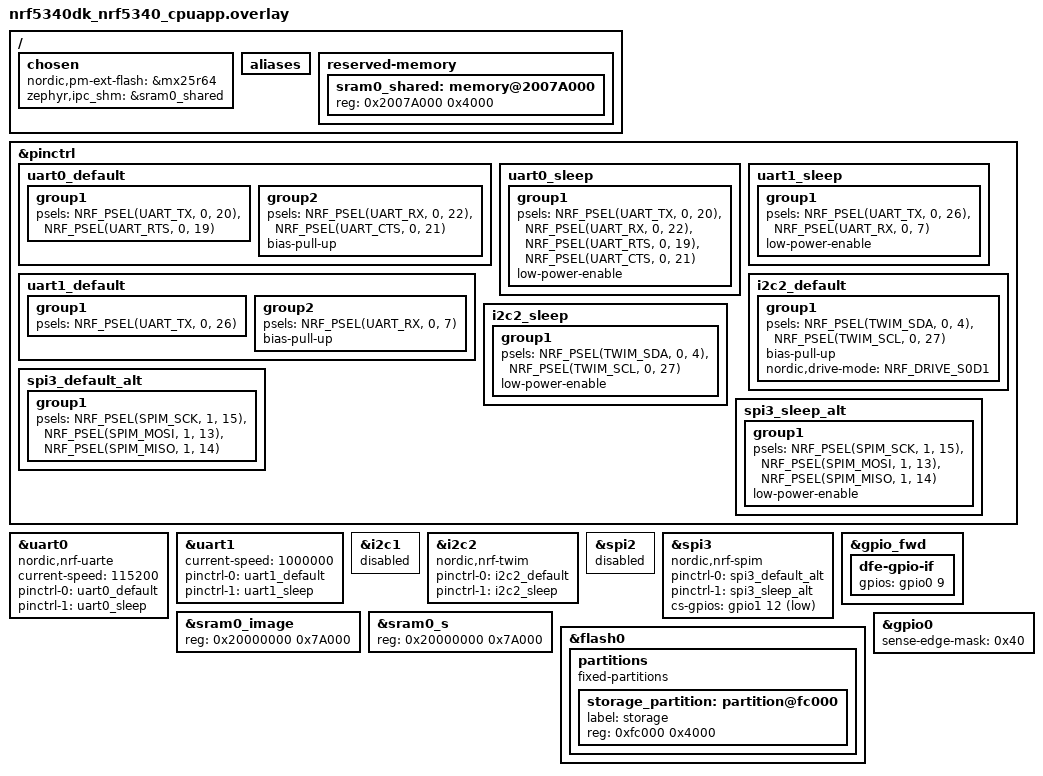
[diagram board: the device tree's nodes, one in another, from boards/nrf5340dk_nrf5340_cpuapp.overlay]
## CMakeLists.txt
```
# SPDX-License-Identifier: Apache-2.0

cmake_minimum_required(VERSION 3.13.1)

# set(mcuboot_DTC_OVERLAY_FILE ${CMAKE_CURRENT_SOURCE_DIR}/child_image/mcuboot.overlay)
find_package(Zephyr REQUIRED HINTS $ENV{ZEPHYR_BASE})
project(comprensive_example)

# NORDIC SDK APP START

target_sources(app PRIVATE src/main.c)

target_sources_ifdef(CONFIG_EXAMPLE_I2C app
                     PRIVATE src/iic_thread.c)
					 
target_sources_ifdef(CONFIG_EXAMPLE_SPIM app
                     PRIVATE src/spi_thread.c)
					 
target_sources_ifdef(CONFIG_EXAMPLE_HS_UART app
                     PRIVATE src/uart_thread.c)
					 
target_sources_ifdef(CONFIG_EXAMPLE_ADC app
                     PRIVATE src/adc_thread.c)
					 
target_sources_ifdef(CONFIG_RPC_REMOTE_API app
                     PRIVATE src/rpc_app_api_general.c src/rpc_app_api.c src/rpc_thread.c)				 

target_sources_ifdef(CONFIG_RPC_SMP_BT app
                     PRIVATE src/rpc_app_smp_bt.c)
					 
target_sources_ifdef(CONFIG_EXAMPLE_FLASH app
                     PRIVATE src/flash_thread.c)

zephyr_library_include_directories(.)

# NORDIC SDK APP END
```

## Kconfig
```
#
# Copyright (c) 2018 Nordic Semiconductor ASA
#
# SPDX-License-Identifier: LicenseRef-BSD-5-Clause-Nordic
#

source "Kconfig.zephyr"
menu "comprehensive_rpc example"

config BLE_NETWORK_CORE
	bool "Both BLE host and controller run on network core"
	help
	  Enable the whole BLE stack running on network core

config EXAMPLE_I2C
	bool "load I2C example or not"
	help
		if yes, load I2C example
		
config EXAMPLE_SPIM
	bool "load SPI master example or not"
	help
		if yes, load SPI master example		
		
config EXAMPLE_EXT_INT
	bool "load external IO interrupt example or not"
	help
		if yes, load external IO interrupt example

config EXAMPLE_ADC
	bool "load ADC example or not"
	help
		if yes, load ADC example		

config EXAMPLE_HS_UART
	bool "load high speed UART example or not"
	help
		if yes, load high speed UART example	  

config EXAMPLE_FLASH
	bool "load Flash access usage example"
	default n
	help
		if yes, load Flash access usage example

config RPC_REMOTE_API
	bool "app core and net core communicate by remote API. that is, app core can call net core API, and net core can also call app core API"
	help
	  enable the RPC api mode
	  
config RPC_SMP_BT
	bool "load DFU example over BLE SMP"
	help
		if yes, load DFU example over BLE SMP

config RPC_REASSEMBLY_BT
	bool "enable reassembly of BT packets"
	select MCUMGR_SMP_REASSEMBLY
	help
		if yes, enable reassembly of BT packets
		
module = COMPREHENSIVE_RPC_EXAMPLE_CONFIG
module-str = comprehensive_rpc example configurations
source "${ZEPHYR_BASE}/subsys/logging/Kconfig.template.log_config"

endmenu
```

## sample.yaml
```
sample:
  name: BLE Comprehensive rpc example
  description: secondary slot on external QSPI flash. Both BT host and controller run on network core.
tests:
  samples.bluetooth.peripheral_uart:
    build_only: true
    build_on_all: true
    platform_allow: nrf5340dk_nrf5340_cpuapp
    tags: bluetooth ci_build
```

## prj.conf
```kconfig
CONFIG_NFCT_PINS_AS_GPIOS=y

## thread monitor ##
CONFIG_THREAD_ANALYZER=y
CONFIG_THREAD_NAME=y

## logging configurations ##
CONFIG_ASSERT=y
CONFIG_LOG=y
CONFIG_LOG_PRINTK=y
CONFIG_LOG_BUFFER_SIZE=8192

## Change logging backend to RTT ##
# CONFIG_LOG_BACKEND_UART=n
# CONFIG_LOG_BACKEND_RTT=y
# CONFIG_USE_SEGGER_RTT=y
# CONFIG_RTT_CONSOLE=y
# CONFIG_UART_CONSOLE=n

## peripherals ##
CONFIG_GPIO=y
CONFIG_DK_LIBRARY=y

## stack size configurations ##
CONFIG_SYSTEM_WORKQUEUE_STACK_SIZE=4096
# CONFIG_ISR_STACK_SIZE=2048
CONFIG_HEAP_MEM_POOL_SIZE=12288
CONFIG_MAIN_STACK_SIZE=2048

## I2C master example ##
CONFIG_EXAMPLE_I2C=y
CONFIG_I2C=y
CONFIG_NRFX_TWIM2=y

## external interrupt example (in IIC thread) ##
CONFIG_EXAMPLE_EXT_INT=y

## high speed uart example ##
CONFIG_EXAMPLE_HS_UART=y
CONFIG_SERIAL=y
CONFIG_UART_ASYNC_API=y
CONFIG_UART_1_ASYNC=y
CONFIG_NRFX_UARTE1=y
CONFIG_UART_1_NRF_HW_ASYNC=y
CONFIG_UART_1_NRF_HW_ASYNC_TIMER=1

## SPI master example ##
CONFIG_EXAMPLE_SPIM=y
CONFIG_SPI=y
CONFIG_NRFX_SPIM3=y

## Load ADC example ##
CONFIG_EXAMPLE_ADC=y
CONFIG_ADC=y
CONFIG_ADC_ASYNC=y
CONFIG_ADC_NRFX_SAADC=y

## Flash access usage example ##
CONFIG_EXAMPLE_FLASH=y
CONFIG_FLASH=y
CONFIG_FLASH_PAGE_LAYOUT=y
CONFIG_FLASH_MAP=y
CONFIG_NVS=y
CONFIG_MPU_ALLOW_FLASH_WRITE=y
CONFIG_SETTINGS=y

## Device power management example ##
CONFIG_PM_DEVICE=y

## RPC example configurations ##
CONFIG_RPC_REMOTE_API=y
CONFIG_NRF_RPC=y
CONFIG_NRF_RPC_CBOR=y
CONFIG_NRF_RPC_THREAD_STACK_SIZE=4096

## Common DFU settings ##
CONFIG_BLE_NETWORK_CORE=y
CONFIG_NRF53_UPGRADE_NETWORK_CORE=y
CONFIG_BOOTLOADER_MCUBOOT=y
CONFIG_BOARD_ENABLE_CPUNET=y

## Open the following configs to run nrf_dfu ##
# CONFIG_NRF_DFU=y
# CONFIG_NRF_DFU_RPC_APP=y
# CONFIG_NRF_DFU_LOG_LEVEL=3
# CONFIG_IMG_MANAGER=y
# CONFIG_MCUBOOT_IMG_MANAGER=y
# CONFIG_IMG_BLOCK_BUF_SIZE=4096

## secondary slot on external Flash ##
CONFIG_PM_PARTITION_SIZE_SETTINGS_STORAGE=0x4000
CONFIG_NORDIC_QSPI_NOR=y
CONFIG_NORDIC_QSPI_NOR_FLASH_LAYOUT_PAGE_SIZE=4096
CONFIG_NORDIC_QSPI_NOR_STACK_WRITE_BUFFER_SIZE=16
CONFIG_STREAM_FLASH=y
CONFIG_STREAM_FLASH_ERASE=y

## Open the following configs to run SMP DFU ##
CONFIG_BOOTLOADER_MCUBOOT=y
CONFIG_MCUMGR=y
CONFIG_MCUMGR_CMD_IMG_MGMT=y
CONFIG_MCUMGR_CMD_OS_MGMT=y
CONFIG_OS_MGMT_TASKSTAT=n
CONFIG_OS_MGMT_ECHO=y
CONFIG_IMG_BLOCK_BUF_SIZE=2048
CONFIG_MCUMGR_BUF_COUNT=8
CONFIG_OS_MGMT_MCUMGR_PARAMS=y
# Enable the storage erase command.
CONFIG_MCUMGR_GRP_ZEPHYR_BASIC=y
CONFIG_MCUMGR_GRP_BASIC_CMD_STORAGE_ERASE=y

CONFIG_RPC_SMP_BT=y

## open the following configurations if you want to get a faster DFU speed
CONFIG_RPC_REASSEMBLY_BT=y
CONFIG_MCUMGR_BUF_SIZE=2475
CONFIG_MCUMGR_BUF_COUNT=4

# FLASH nop device is enabled to prevent bus faults when mcumgr tries to access
# simulated partition with network core image data.
# CONFIG_FLASH_NOP_DEVICE=y

# update application core and network core together in a zip file
CONFIG_MCUBOOT_IMAGE_VERSION="1.0.0+0"
CONFIG_UPDATEABLE_IMAGE_NUMBER=2
CONFIG_IMG_ERASE_PROGRESSIVELY=y
CONFIG_NRF53_UPGRADE_NETWORK_CORE=y
```

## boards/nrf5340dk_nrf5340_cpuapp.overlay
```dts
/* overlay file for app core */

/ {
	chosen {
		nordic,pm-ext-flash = &mx25r64;
	};
};

&pinctrl {
	uart0_default: uart0_default {
		group1 {
			psels = <NRF_PSEL(UART_TX, 0, 20)>,
				<NRF_PSEL(UART_RTS, 0, 19)>;
		};
		group2 {
			psels = <NRF_PSEL(UART_RX, 0, 22)>,
				<NRF_PSEL(UART_CTS, 0, 21)>;
			bias-pull-up;
		};
	};

	uart0_sleep: uart0_sleep {
		group1 {
			psels = <NRF_PSEL(UART_TX, 0, 20)>,
				<NRF_PSEL(UART_RX, 0, 22)>,
				<NRF_PSEL(UART_RTS, 0, 19)>,
				<NRF_PSEL(UART_CTS, 0, 21)>;
			low-power-enable;
		};
	};

	uart1_default: uart1_default {
		group1 {
			psels = <NRF_PSEL(UART_TX, 0, 26)>;
		};
		group2 {
			psels = <NRF_PSEL(UART_RX, 0, 7)>;
			bias-pull-up;
		};
	};

	uart1_sleep: uart1_sleep {
		group1 {
			psels = <NRF_PSEL(UART_TX, 0, 26)>,
				<NRF_PSEL(UART_RX, 0, 7)>;
			low-power-enable;
		};
	};

	i2c2_default: i2c2_default {
		group1 {
			psels = <NRF_PSEL(TWIM_SDA, 0, 4)>,
				<NRF_PSEL(TWIM_SCL, 0, 27)>;
			bias-pull-up;
			nordic,drive-mode = <NRF_DRIVE_S0D1>;				
		};
	};

	i2c2_sleep: i2c2_sleep {
		group1 {
			psels = <NRF_PSEL(TWIM_SDA, 0, 4)>,
				<NRF_PSEL(TWIM_SCL, 0, 27)>;
			low-power-enable;
		};
	};	

	spi3_default_alt: spi3_default_alt {
		group1 {
			psels = <NRF_PSEL(SPIM_SCK, 1, 15)>,
				<NRF_PSEL(SPIM_MOSI, 1, 13)>,
				<NRF_PSEL(SPIM_MISO, 1, 14)>;
		};
	};

	spi3_sleep_alt: spi3_sleep_alt {
		group1 {
			psels = <NRF_PSEL(SPIM_SCK, 1, 15)>,
				<NRF_PSEL(SPIM_MOSI, 1, 13)>,
				<NRF_PSEL(SPIM_MISO, 1, 14)>;
			low-power-enable;
		};
	};
};


&uart0 {
	compatible = "nordic,nrf-uarte";
	status = "okay";
	current-speed = < 115200 >;
	pinctrl-0 = < &uart0_default >;
	pinctrl-1 = < &uart0_sleep >;
	pinctrl-names = "default", "sleep";	
	/* delete rts-pin&cts-pin to release the related 2 pins for other uses */
	/delete-property/ rts-pin;
	/delete-property/ cts-pin;
};

&uart1 {
	status = "okay";
	current-speed = < 1000000 >;
	pinctrl-0 = < &uart1_default >;
	pinctrl-1 = < &uart1_sleep >;
	pinctrl-names = "default", "sleep";	
};

&i2c1 {
	status = "disabled";
};

my_i2c: &i2c2 {
	status = "okay";
	compatible = "nordic,nrf-twim";
	pinctrl-0 = < &i2c2_default >;
	pinctrl-1 = < &i2c2_sleep >;
	pinctrl-names = "default", "sleep";	
};

&spi2 {
	status = "disabled";
};

my_spi: &spi3 {
	status = "okay"; 
	compatible = "nordic,nrf-spim";
	pinctrl-0 = <&spi3_default_alt>;
	pinctrl-1 = <&spi3_sleep_alt>;
	pinctrl-names = "default", "sleep";	
	cs-gpios = <&gpio1 12 GPIO_ACTIVE_LOW>;
};

/* delete button4 to initialize the related pin for network core use */
/ {
 aliases {  
  /delete-property/ sw3;
 };
};

/delete-node/ &button3;

&gpio_fwd {
	dfe-gpio-if {
		gpios = <&gpio0 9 0>;
		};
};

/* adjust the RAM size of application image */
&sram0_image{
	reg = < 0x20000000 0x7A000 >;
};

&sram0_s{
	reg = < 0x20000000 0x7A000 >;
};

/delete-node/ &sram0_shared;

/ {
	chosen {
		/* shared memory reserved for the inter-processor communication */
		zephyr,ipc_shm = &sram0_shared;
	};

	reserved-memory {
		#address-cells = <1>;
		#size-cells = <1>;
		ranges;	
		sram0_shared: memory@2007A000 {
			/* SRAM allocated to shared memory */
			reg = <0x2007A000 0x4000>;
		};
	};
};

/delete-node/ &storage_partition;
&flash0{
		partitions {
			compatible = "fixed-partitions";
			#address-cells = < 0x1 >;
			#size-cells = < 0x1 >;

			storage_partition: partition@fc000 {
				label = "storage";
				reg = < 0xfc000 0x4000 >;
			};
		};
};

&gpio0 {
	/* pin6 sense for edge */
	sense-edge-mask = <0x40>;
};
```

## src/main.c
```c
/*
 * Copyright (c) 2020 Nordic Semiconductor ASA
 *
 * SPDX-License-Identifier: LicenseRef-BSD-5-Clause-Nordic
 */

#include <zephyr/kernel.h>
#include <zephyr/device.h>
#include <zephyr/devicetree.h>
#include <zephyr/drivers/gpio.h>
#include <stdio.h>
#include <dk_buttons_and_leds.h>
#include <nrf.h>
#include <nrfx.h>
#include <zephyr/drivers/uart.h>
#ifdef CONFIG_MCUMGR_CMD_IMG_MGMT
#include "img_mgmt/img_mgmt.h"
#endif
#ifdef CONFIG_MCUMGR_CMD_OS_MGMT
#include "os_mgmt/os_mgmt.h"
#endif
#ifdef CONFIG_RPC_SMP_BT
#include "rpc_app_smp_bt.h"
#include <img_mgmt/img_mgmt_impl.h>
#endif
#ifdef CONFIG_NRF_DFU
#include "nrf_dfu_settings.h"
#include "nrf_dfu.h"
#include <zephyr/sys/reboot.h>
#include "nrf_dfu.h"
#include "nrf_dfu_validation.h"
#endif
#include <zephyr/logging/log.h>
#include <zephyr/logging/log_ctrl.h>
#include <zephyr/pm/device.h>

#define LOG_MODULE_NAME main
LOG_MODULE_REGISTER(LOG_MODULE_NAME);

#define ERASE_DELAY_AFTER_BOOT 30   //unit: s
static struct k_work_delayable blinky_work;

K_SEM_DEFINE(sem_rpc_tx, 0, 1);
K_SEM_DEFINE(sem_spi_txrx, 0, 1);

/* Stack definition for application workqueue */
K_THREAD_STACK_DEFINE(application_stack_area,
		      1024);
static struct k_work_q application_work_q;

/* The devicetree node identifier for the "led0" alias. */
#define LED0_NODE DT_ALIAS(led0)

#if DT_NODE_HAS_STATUS(LED0_NODE, okay)
#define LED0	DT_GPIO_CTLR(LED0_NODE, gpios)
#define LED0_PIN	DT_GPIO_PIN(LED0_NODE, gpios)
#define LED0_FLAGS	DT_GPIO_FLAGS(LED0_NODE, gpios)
#else
/* A build error here means your board isn't set up to blink an LED. */
#error "Unsupported board: led0 devicetree alias is not defined"
#define LED0	""
#define PIN	0
#define FLAGS	0
#endif

#ifdef CONFIG_PM_DEVICE
const struct device *devUart0;
const struct device *devUart1;
static void get_device_handles(void)
{
	devUart0 = device_get_binding("UART_0");
    devUart1 = device_get_binding("UART_1");
}

void set_device_pm_state(void)
{
	int err;
	enum pm_device_state pm_state;

	if (devUart1)
	{
		pm_device_state_get(devUart1, &pm_state);
		if (pm_state == PM_DEVICE_STATE_SUSPENDED)
		{
			LOG_INF("UART1 is in low power state. We activate it");
			err = pm_device_action_run(devUart1,PM_DEVICE_ACTION_RESUME);
			if (err) {
				LOG_ERR("UART1 enable failed");			
			}
			else
			{
				LOG_INF("## UART1 is active now ##");
			}		
		}
		else if (pm_state == PM_DEVICE_STATE_ACTIVE)
		{
			LOG_INF("UART1 is in active state. We suspend it");

#if CONFIG_UART_ASYNC_API && CONFIG_UART_1_NRF_HW_ASYNC
		((const struct uart_driver_api *)devUart1->api)->rx_disable(devUart1);
#endif			
			err = pm_device_action_run(devUart1,	PM_DEVICE_ACTION_SUSPEND);
			if (err) {
				LOG_ERR("UART1 disable failed");
			}
			else
			{
				LOG_INF("## UART1 is suspended now ##");
			}		
		}
	}

	pm_device_state_get(devUart0, &pm_state);
	if (pm_state == PM_DEVICE_STATE_SUSPENDED)
	{
		LOG_INF("UART0 is in low power state. We activate it");
		err = pm_device_action_run(devUart0,	PM_DEVICE_ACTION_RESUME);
		if (err) {
			LOG_ERR("UART0 enable failed");			
		}
		else
		{
			LOG_INF("## UART0 is active now ##");
		}		
	}
	else if (pm_state == PM_DEVICE_STATE_ACTIVE)
	{
		LOG_INF("UART0 is in active state. We suspend it");
		//print out all the pending logging messages
		while(log_process());

#if CONFIG_UART_ASYNC_API && CONFIG_UART_0_NRF_HW_ASYNC
		((const struct uart_driver_api *)devUart0->api)->rx_disable(devUart0);
#endif
		err = pm_device_action_run(devUart0,	PM_DEVICE_ACTION_SUSPEND);
		if (err) {
			LOG_ERR("UART0 disable failed");
		}
		else
		{
			LOG_INF("## UART0 is suspended now ##");
		}		
	}

}

#endif //CONFIG_PM_DEVICE

void button_changed(uint32_t button_state, uint32_t has_changed)
{
	uint32_t buttons = button_state & has_changed;
	
	if (buttons & DK_BTN1_MSK) {
		LOG_INF("button1 isr");
		k_sem_give(&sem_rpc_tx);		
	}

	if (buttons & DK_BTN2_MSK) {
		LOG_INF("button2 isr");
		k_sem_give(&sem_spi_txrx);
	}

	if (buttons & DK_BTN3_MSK) {
		LOG_INF("button3 isr");
#ifdef CONFIG_PM_DEVICE		
		set_device_pm_state();
#endif		
	}			
}

const struct device *ledDev;
bool led_is_on = true;

static void blinky_work_fn(struct k_work *work)
{
    //printk("blinky fn in system workqueue\n");
	gpio_pin_set(ledDev, LED0_PIN, (int)led_is_on);
	led_is_on = !led_is_on;

	k_work_reschedule_for_queue(&application_work_q, &blinky_work,
					   	K_SECONDS(2));

}

static void assign_io_to_netcore(void)
{
	NRF_P0_S->PIN_CNF[9] = (GPIO_PIN_CNF_MCUSEL_NetworkMCU <<
					GPIO_PIN_CNF_MCUSEL_Pos);
}

#ifdef CONFIG_NRF_DFU
/**@brief Function for handling DFU events.
 */
static void dfu_observer(nrf_dfu_evt_type_t evt_type)
{
    switch (evt_type)
    {
        case NRF_DFU_EVT_DFU_STARTED:
        case NRF_DFU_EVT_OBJECT_RECEIVED:

            break;
        case NRF_DFU_EVT_DFU_COMPLETED:
        case NRF_DFU_EVT_DFU_ABORTED:
			LOG_INF("resetting...");
			while(log_process());
            sys_reboot(SYS_REBOOT_WARM);
            break;
        case NRF_DFU_EVT_TRANSPORT_DEACTIVATED:
            // Reset the internal state of the DFU settings to the last stored state.
			LOG_INF("NRF_DFU_EVT_TRANSPORT_DEACTIVATED");
            nrf_dfu_settings_reinit();
            break;
        default:
            break;
    }

}

int dfu_init(void)
{
    int ret_val;

    ret_val = nrf_dfu_settings_init(true);
    if (ret_val != NRF_SUCCESS)
	{
		LOG_WRN("dfu settings init err %d", ret_val);
	}

    ret_val = nrf_dfu_init(dfu_observer);
    if (ret_val != NRF_SUCCESS)
	{
		LOG_WRN("dfu init err %d", ret_val);
	}

    return ret_val;
}
#endif //CONFIG_NRF_DFU

void main(void)
{
	int err;	

	LOG_INF("### comprehensive example @ appcore version v0.5 compiled at %s %s\n", __TIME__, __DATE__);
	// assign_io_to_netcore();  //It's now replaced by device tree configurations

	ledDev = DEVICE_DT_GET(LED0);
	if (ledDev == NULL) {
		return;
	}

#ifdef CONFIG_PM_DEVICE
	get_device_handles();
#endif

	err = gpio_pin_configure(ledDev, LED0_PIN, GPIO_OUTPUT_ACTIVE | LED0_FLAGS);
	if (err < 0) {
		printk("gpio configure error %d \n", err);
		return;
	}

	err = dk_buttons_init(button_changed);
	if (err) {
		printk("Cannot init buttons (err: %d)", err);
	}

	k_work_queue_start(&application_work_q, application_stack_area,
			   K_THREAD_STACK_SIZEOF(application_stack_area), 10,
			   NULL);
	k_work_init_delayable(&blinky_work, blinky_work_fn);
	k_work_reschedule_for_queue(&application_work_q, &blinky_work,
					   	K_MSEC(20));	

#ifdef CONFIG_RPC_SMP_BT
	LOG_INF("## OTA/Serial DFU example ##");	
#ifdef CONFIG_MCUMGR_CMD_OS_MGMT
	os_mgmt_register_group();
#endif	
#ifdef CONFIG_MCUMGR_CMD_IMG_MGMT
	img_mgmt_register_group();
#endif //CONFIG_MCUMGR_CMD_IMG_MGMT
#endif  //CONFIG_RPC_SMP_BT

#ifdef CONFIG_NRF_DFU
	err = dfu_init();
	if (err) {
		LOG_ERR("dfu service init err %d", err);		
	}
#endif //CONFIG_NRF_DFU
	//main thread 
	while(1)
	{
		//add your code here
		k_sleep(K_SECONDS(5));
		LOG_INF("main thread");
	}
}
```

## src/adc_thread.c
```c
/*
 * Copyright (c) 2020 Nordic Semiconductor ASA
 *
 * SPDX-License-Identifier: LicenseRef-BSD-5-Clause-Nordic
 */

#include <zephyr/zephyr.h>
#include <zephyr/device.h>
#include <zephyr/devicetree.h>
#include <zephyr/drivers/gpio.h>
#include <zephyr/logging/log.h>
#include <zephyr/drivers/adc.h>
#include <hal/nrf_saadc.h>

LOG_MODULE_REGISTER(adc_thread, 3);

#define NUM_OF_CH 2
#define ADC_DEVICE_NAME		DT_LABEL(DT_NODELABEL(adc))
#define ADC_RESOLUTION		12
#define ADC_OVERSAMPLING	4 /* 2^ADC_OVERSAMPLING samples are averaged */
#define ADC_MAX 		4096
#define BATTERY_MEAS_VOLTAGE_GAIN	6
#define ADC_GAIN		ADC_GAIN_1_6
#define ADC_REFERENCE		ADC_REF_INTERNAL
#define ADC_REF_INTERNAL_MV	600UL
#define ADC_ACQUISITION_TIME	ADC_ACQ_TIME(ADC_ACQ_TIME_MICROSECONDS, 10)
#define ADC_CHANNEL_ID		0
#define ADC_CHANNEL_INPUT	NRF_SAADC_INPUT_VDD
#define ADC_CHANNEL_ID2		1
#define ADC_CHANNEL_INPUT2	NRF_SAADC_INPUT_AIN1   //P0.05
/* ADC asynchronous read is scheduled on odd works. Value read happens during
 * even works. This is done to avoid creating a thread for battery monitor.
 */
#define ADC_SAMPLE_INTERVAL	20  //unit:s

#define BATTERY_VOLTAGE(sample) (sample * BATTERY_MEAS_VOLTAGE_GAIN	\
				 * ADC_REF_INTERNAL_MV / ADC_MAX)


static const struct device *adc_dev;
static int16_t adc_buffer[NUM_OF_CH];
static bool adc_async_read_pending;
static struct k_work_delayable adc_work;

static struct k_poll_signal async_sig = K_POLL_SIGNAL_INITIALIZER(async_sig);
static struct k_poll_event  async_evt =
	K_POLL_EVENT_INITIALIZER(K_POLL_TYPE_SIGNAL,
				 K_POLL_MODE_NOTIFY_ONLY,
				 &async_sig);

static struct adc_sequence sequence = {
	.options	= NULL,
	.channels	= BIT(ADC_CHANNEL_ID),
	.buffer		= adc_buffer,
	.buffer_size	= sizeof(adc_buffer),
	.resolution	= ADC_RESOLUTION,
	.oversampling	= ADC_OVERSAMPLING,
	.calibrate	= false,
};
static struct adc_sequence sequence_calibrate = {
	.options	= NULL,
	.channels	= BIT(ADC_CHANNEL_ID),
	.buffer		= adc_buffer,
	.buffer_size	= sizeof(adc_buffer),
	.resolution	= ADC_RESOLUTION,
	.oversampling	= ADC_OVERSAMPLING,
	.calibrate	= true,
};

static bool calibrated;

void adc_sample_sync(void)
{
	int err;

	if (NUM_OF_CH == 2)
	{
		sequence.channels = BIT(ADC_CHANNEL_ID) | BIT(ADC_CHANNEL_ID2);
		sequence_calibrate.channels = BIT(ADC_CHANNEL_ID) | BIT(ADC_CHANNEL_ID2);
		sequence.oversampling  = NRF_SAADC_OVERSAMPLE_DISABLED;
		sequence_calibrate.oversampling  = NRF_SAADC_OVERSAMPLE_DISABLED;
	}
	if (likely(calibrated)) {		
		err = adc_read(adc_dev, &sequence);
	} else {
		err = adc_read(adc_dev, &sequence_calibrate);
		calibrated = true;
	}
	if (err) {
		LOG_WRN("ADC read err %d", err);
	} else {
		for (int i = 0; i < NUM_OF_CH; i++)
		{
			uint32_t voltage = BATTERY_VOLTAGE(adc_buffer[i]);
			LOG_INF("Voltage%d: %u mV / %d", i, voltage, adc_buffer[i]);
		}
	}			
}
#ifdef CONFIG_ADC_ASYNC
static void adc_sample_async(struct k_work *work)
{
	int err;

	if (NUM_OF_CH == 2)
	{
		sequence.channels = BIT(ADC_CHANNEL_ID) | BIT(ADC_CHANNEL_ID2);
		sequence_calibrate.channels = BIT(ADC_CHANNEL_ID) | BIT(ADC_CHANNEL_ID2);
		sequence.oversampling  = NRF_SAADC_OVERSAMPLE_DISABLED;
		sequence_calibrate.oversampling  = NRF_SAADC_OVERSAMPLE_DISABLED;		
	}
	if (!adc_async_read_pending) {
		if (likely(calibrated)) {
			err = adc_read_async(adc_dev, &sequence, &async_sig);
		} else {
			err = adc_read_async(adc_dev, &sequence_calibrate,
					     &async_sig);
			calibrated = true;
		}

		if (err) {
			LOG_WRN("adc_read_async err %d", err);
		} else {
			adc_async_read_pending = true;
		}
	} else {
		err = k_poll(&async_evt, 1, K_NO_WAIT);
		if (err) {
			LOG_WRN("ADC sampling timeout");
		} else {
			adc_async_read_pending = false;			
			for (int i = 0; i < NUM_OF_CH; i++)
			{
				uint32_t voltage = BATTERY_VOLTAGE(adc_buffer[i]);
				LOG_INF("Voltage%d: %u mV / %d async", i, voltage, adc_buffer[i]);
			}			
		}
	}

	k_work_reschedule(&adc_work, K_SECONDS(ADC_SAMPLE_INTERVAL));

}
#endif

static int init_adc(void)
{
	int err;

	adc_dev = device_get_binding(ADC_DEVICE_NAME);
	if (!adc_dev) {
		LOG_ERR("Cannot get ADC device");
		return -ENXIO;
	}

	struct adc_channel_cfg channel_cfg = {
		.gain             = ADC_GAIN,
		.reference        = ADC_REFERENCE,
		.acquisition_time = ADC_ACQUISITION_TIME,
		.channel_id       = ADC_CHANNEL_ID,
		.differential	  = 0,
#if defined(CONFIG_ADC_CONFIGURABLE_INPUTS)
		.input_positive   = ADC_CHANNEL_INPUT,
#endif
	};
	err = adc_channel_setup(adc_dev, &channel_cfg);
	if (err) {
		LOG_ERR("Setting up the ADC channel%d failed", ADC_CHANNEL_ID);
		return err;
	}

	if (NUM_OF_CH == 2)
	{
		channel_cfg.channel_id = ADC_CHANNEL_ID2;
		channel_cfg.input_positive = ADC_CHANNEL_INPUT2;
		err = adc_channel_setup(adc_dev, &channel_cfg);
		if (err) {
			LOG_ERR("Setting up the ADC channel%d failed", ADC_CHANNEL_ID2);
			return err;
		}		
	}


#ifdef CONFIG_ADC_ASYNC
	k_work_init_delayable(&adc_work, adc_sample_async);
	k_work_reschedule(&adc_work, K_MSEC(10));
#endif //CONFIG_ADC_ASYNC

	return 0;
}


void adc_thread(void)
{	
	
	LOG_INF("**ADC sampling example");
	init_adc();

	while (1) {                
        LOG_INF("ADC thread");
        adc_sample_sync();
        k_sleep(K_SECONDS(ADC_SAMPLE_INTERVAL)); 
	}
}

K_THREAD_DEFINE(adc_thread_id, 1024, adc_thread, NULL, NULL,
		NULL, 8, 0, 0);
```

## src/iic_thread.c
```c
/*
 * Copyright (c) 2020 Nordic Semiconductor ASA
 *
 * SPDX-License-Identifier: LicenseRef-BSD-5-Clause-Nordic
 */

#include <zephyr/kernel.h>
#include <zephyr/device.h>
#include <zephyr/devicetree.h>
#include <zephyr/drivers/gpio.h>
#include <zephyr/drivers/i2c.h>
#include <zephyr/logging/log.h>

#define LOG_MODULE_NAME i2c_thread
LOG_MODULE_REGISTER(LOG_MODULE_NAME);

const struct device *i2c_dev;
const static struct device *gpio_dev;
//static struct k_delayed_work read_eeprom;
K_SEM_DEFINE(sem_iic_op, 0, 1);

#define EXT_INT_IO	6  //p0.06
#define EXT_INT_CONF	(GPIO_INPUT | GPIO_PULL_UP)

static struct gpio_callback ext_int_cb_data;

#define EEPROM_SIM_SIZE                   (320u) //!< Simulated EEPROM size.

#define EEPROM_SIM_ADDR                   0x50    //!< Simulated EEPROM TWI slave address.

/* Slave memory addressing byte length */
#define EEPROM_SIM_ADDRESS_LEN_BYTES    2

#define IN_LINE_PRINT_CNT   (16u)   //!< Number of data bytes printed in a single line.


static int eeprom_read(uint16_t addr, uint8_t * pdata, size_t size)
{
    int ret;
    if (size > (EEPROM_SIM_SIZE))
    {
        return EINVAL;
    }
    do
    {
       uint16_t addr16 = addr;
       ret = i2c_write(i2c_dev, (uint8_t *)&addr16, EEPROM_SIM_ADDRESS_LEN_BYTES, EEPROM_SIM_ADDR);
       if (0 != ret)
       {
           break;
       }
       ret = i2c_read(i2c_dev, pdata, size, EEPROM_SIM_ADDR);
    }while (0);
    return ret;
}

static void eeprom_cmd_read(void)
{    
    uint8_t buf[IN_LINE_PRINT_CNT+1];

    for (uint16_t addr = 0; addr < EEPROM_SIM_SIZE; addr += IN_LINE_PRINT_CNT)
    {
        int err_code;
        err_code = eeprom_read(addr, buf, IN_LINE_PRINT_CNT);
        buf[IN_LINE_PRINT_CNT] = '\0';
        if (0 != err_code)
        {
            LOG_ERR("EEPROM transmission error %d\n", err_code);
            return;
        }

        LOG_HEXDUMP_INF(buf, IN_LINE_PRINT_CNT, "EEPROM: ");        
      
    }
}


void ext_int_isr(const struct device *dev, struct gpio_callback *cb,
		    uint32_t pins)
{
	LOG_INF("external interrupt occurs at %x", pins);   
    k_sem_give(&sem_iic_op);    
}

#ifdef CONFIG_EXAMPLE_EXT_INT
void config_io_interrupt(void)
{
	int ret;

	gpio_dev = device_get_binding(DT_NODE_FULL_NAME(DT_NODELABEL(gpio0)));
	if (!gpio_dev) {
		LOG_ERR("Error: didn't find GPIO_0\n");
		return;
	}

	ret = gpio_pin_configure(gpio_dev, EXT_INT_IO, EXT_INT_CONF);
	if (ret != 0) {
		LOG_ERR("Error %d: failed to configure pin %d\n",
		       ret, EXT_INT_IO);
	}

	ret = gpio_pin_interrupt_configure(gpio_dev,
					   EXT_INT_IO,
					   GPIO_INT_EDGE_FALLING);
	if (ret != 0) {
		LOG_ERR("Error %d: failed to configure interrupt on pin %d\n",
			ret, EXT_INT_IO);
	}

	gpio_init_callback(&ext_int_cb_data, ext_int_isr, BIT(EXT_INT_IO));
	gpio_add_callback(gpio_dev, &ext_int_cb_data);
	LOG_INF("**External interrupt example at P0.%d\n", EXT_INT_IO);
}
#endif //CONFIG_EXAMPLE_EXT_INT

void iic_thread(void)
{
	
	LOG_INF("** I2C master example **");
	LOG_INF("This example is ported from nRF5_SDK\\examples\\peripheral\\twi_master_with_twis_slave");
	LOG_INF("The related twis example is from nRF5_SDK\\examples\\peripheral\\twi_master_with_twis_slave");	
	
	i2c_dev = device_get_binding(DT_NODE_FULL_NAME(DT_NODELABEL(my_i2c)));
	if (!i2c_dev) {
		LOG_ERR("I2C Device driver not found");
		return;
	}
    uint32_t i2c_cfg = I2C_SPEED_SET(I2C_SPEED_FAST) | I2C_MODE_MASTER;
    if (i2c_configure(i2c_dev, i2c_cfg)) {
        LOG_ERR("I2C config failed");
        return;
    }
#ifdef CONFIG_EXAMPLE_EXT_INT
    config_io_interrupt();    
#endif
    
	// k_delayed_work_init(&read_eeprom, eeprom_read_fn);
    // k_delayed_work_submit(&read_eeprom, K_MSEC(50));	    

	while (1) {        
        k_sem_take(&sem_iic_op, K_FOREVER);
        LOG_INF("i2c master thread");
        eeprom_cmd_read();
        k_sleep(K_SECONDS(2));
	}
}

K_THREAD_DEFINE(iic_thread_id, 1024, iic_thread, NULL, NULL,
		NULL, 7, 0, 0);
```

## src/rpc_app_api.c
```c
/*
 * Copyright (c) 2020 Nordic Semiconductor ASA
 *
 * SPDX-License-Identifier: LicenseRef-BSD-5-Clause-Nordic
 */

#include <zephyr/zephyr.h>
#include <zephyr/device.h>
#include <zephyr/devicetree.h>
#include <zephyr/drivers/gpio.h>
#include <stdio.h>
#include "rpc_app_api.h"
#include "nrf_rpc_tr.h"
#include <zephyr/logging/log.h>
#include <zephyr/drivers/uart.h>
#include "common_ids.h"

#define LOG_MODULE_NAME rpc_app_api
LOG_MODULE_REGISTER(LOG_MODULE_NAME);

uint8_t bt_addr[6];
static bool m_connected = false;

int app2net_send_nus(uint8_t *data, uint16_t len)
{
	return rpc_app2net_send(APP2NET_BT_NUS_SEND, data, len);
}


int net2app_receive_bt_addr(uint8_t *buf, uint16_t len)
{	
	memcpy(bt_addr, &buf[1], 6);
	
	LOG_HEXDUMP_INF(&buf[1], 6, "===bt dev addr: ===");
	LOG_INF("addr type %d", buf[0]);

	return 0;
}

#ifdef CONFIG_EXAMPLE_HS_UART
extern int my_uart_send(const uint8_t *buf, size_t len);
#endif

int net2app_receive_nus(uint8_t *buf, uint16_t len)
{
	LOG_HEXDUMP_INF(buf, len, "===nus data: ===");

#ifdef CONFIG_EXAMPLE_HS_UART
	my_uart_send(buf, len);
#endif	
	return 0;
}

int net2app_receive_conn_status(uint8_t *data, uint16_t len)
{
	if (data[0] == 1)
	{
		m_connected = true;
	}
	else
	{
		m_connected = false;
	}

	return 0;
}

bool is_ble_connected(void)
{
	return m_connected;
}

int net2app_receive(int type, uint8_t *data, size_t len)
{
	int err = 0; 

	switch (type)
	{
		case NET2APP_BT_ADDR_SEND:
			err = net2app_receive_bt_addr(data, len);
			break;
		case NET2APP_BT_NUS_RECV:
			err = net2app_receive_nus(data, len);
			break;
		case NET2APP_BT_CONN_STATUS:
			err = net2app_receive_conn_status(data, len);
			break;			
		default:
			LOG_INF("undefined command or cbor error");
			break;
	}

	return err;	
}
```

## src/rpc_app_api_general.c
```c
/*
 * Copyright (c) 2020 Nordic Semiconductor ASA
 *
 * SPDX-License-Identifier: LicenseRef-BSD-5-Clause-Nordic
 */
#include <errno.h>
#include <zephyr/init.h>
#include <string.h>
#include <nrf_rpc/nrf_rpc_ipc.h>
#include <nrf_rpc_cbor.h>
#include <zcbor_common.h>
#include <zcbor_decode.h>
#include <zcbor_encode.h>
#include "common_ids.h"
#include <zephyr/logging/log.h>
#include "rpc_app_api.h"

#define LOG_MODULE_NAME rpc_app_api_general
LOG_MODULE_REGISTER(LOG_MODULE_NAME);
#define CBOR_BUF_SIZE 16

NRF_RPC_IPC_TRANSPORT(rpc_api_tr, DEVICE_DT_GET(DT_NODELABEL(ipc0)), "nrf_rpc_ept_2");
NRF_RPC_GROUP_DEFINE(rpc_api, "RPC_API", &rpc_api_tr, NULL, NULL, NULL);

static void rsp_error_code_handle(const struct nrf_rpc_group *group, struct nrf_rpc_cbor_ctx *ctx,
			   void *handler_data)
{
	int32_t val;

	if (zcbor_int32_decode(ctx->zs, &val)) {
		*(int *)handler_data = (int)val;
	} else {
		*(int *)handler_data = -NRF_EINVAL;
	}
}

static void rsp_error_code_send(const struct nrf_rpc_group *group, int err_code)
{
	struct nrf_rpc_cbor_ctx ctx;

	NRF_RPC_CBOR_ALLOC(group, ctx, CBOR_BUF_SIZE);
	zcbor_int32_put(ctx.zs, err_code);

	nrf_rpc_cbor_rsp_no_err(group, &ctx);
}

int rpc_app2net_send(int32_t type, uint8_t *buffer, int32_t length)
{
	int err;
	int32_t result = 0;
	struct nrf_rpc_cbor_ctx ctx;

	printk("buf:%p, len:%d \r", buffer, length);
	if (!buffer || length < 1) {
		return -NRF_EINVAL;
	}	

	NRF_RPC_CBOR_ALLOC(&rpc_api, ctx, CBOR_BUF_SIZE + length);
	
	zcbor_int32_put(ctx.zs, type);
	zcbor_int32_put(ctx.zs, length);
	zcbor_bstr_encode_ptr(ctx.zs, buffer, length);	

	err = nrf_rpc_cbor_cmd(&rpc_api, RPC_COMMAND_APP_SEND, &ctx,
			       rsp_error_code_handle, &result);
	//printk("err %d result %d\r", err, result);
	if (err) {
		return err;
	}

	return result;
}

static void rpc_net2app_send(const struct nrf_rpc_group *group, struct nrf_rpc_cbor_ctx *ctx, void *handler_data)
{	
	struct zcbor_string zst;
	int err_code = -NRF_EINVAL;
	size_t length;
	uint8_t buf[256];
	int type;
	

	if (!zcbor_int32_decode(ctx->zs, &type)) {
		goto cbor_error_exit;
	}

	if (!zcbor_int32_decode(ctx->zs, &length) || length > ARRAY_SIZE(buf)) {
		goto cbor_error_exit;
	}
	
	if (!zcbor_bstr_decode(ctx->zs, &zst) || zst.len != length) {
		goto cbor_error_exit;
	}
	memcpy(buf, zst.value, zst.len);
	err_code = net2app_receive(type, buf, length);

cbor_error_exit:
	nrf_rpc_cbor_decoding_done(group, ctx);
	rsp_error_code_send(group, err_code);
}


NRF_RPC_CBOR_CMD_DECODER(rpc_api, rpc_net2app_send_name,
			 RPC_COMMAND_NET_SEND,
			 rpc_net2app_send, NULL);


static void err_handler(const struct nrf_rpc_err_report *report)
{
	printk("nRF RPC error %d ocurred. See nRF RPC logs for more details.",
	       report->code);
	k_oops();
}


static int serialization_init(const struct device *dev)
{
	ARG_UNUSED(dev);

	int err;

	printk("Init begin\n");

	err = nrf_rpc_init(err_handler);
	if (err) {
		return -NRF_EINVAL;
	}

	printk("Init done\n");

	return 0;
}


SYS_INIT(serialization_init, POST_KERNEL, CONFIG_APPLICATION_INIT_PRIORITY);
```

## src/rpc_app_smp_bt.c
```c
/*
 * Copyright (c) 2020 Nordic Semiconductor ASA
 *
 * SPDX-License-Identifier: LicenseRef-BSD-5-Clause-Nordic
 */
#include <errno.h>
#include <zephyr/init.h>
#include <string.h>
#include <nrf_rpc/nrf_rpc_ipc.h>
#include <nrf_rpc_cbor.h>
#include <zcbor_common.h>
#include <zcbor_decode.h>
#include <zcbor_encode.h>
#include "common_ids.h"
#include <zephyr/mgmt/mcumgr/smp.h>
#include "smp_reassembly.h"
#include "smp/smp.h"
#include <zephyr/net/buf.h>
#include <zephyr/logging/log.h>

LOG_MODULE_REGISTER(rpc_app_smp, 3);

#define CBOR_BUF_SIZE 16
static struct smp_transport smp_rpc_transport;

NRF_RPC_IPC_TRANSPORT(rpc_smp_tr, DEVICE_DT_GET(DT_NODELABEL(ipc0)), "nrf_rpc_ept_1");
NRF_RPC_GROUP_DEFINE(rpc_smp, "RPC_SMP", &rpc_smp_tr, NULL, NULL, NULL);

static void rsp_error_code_send(const struct nrf_rpc_group *group, int err_code)
{
	struct nrf_rpc_cbor_ctx ctx;

	NRF_RPC_CBOR_ALLOC(group, ctx, CBOR_BUF_SIZE);
	zcbor_int32_put(ctx.zs, err_code);

	nrf_rpc_cbor_rsp_no_err(group, &ctx);
}

static int smp_receive_data(const void *buf, uint16_t len)
{
	LOG_HEXDUMP_DBG(buf, len, "rpc app smp rx:");

#ifdef CONFIG_RPC_REASSEMBLY_BT
	int ret;
	bool started;

	started = (smp_reassembly_expected(&smp_rpc_transport) >= 0);
	ret = smp_reassembly_collect(&smp_rpc_transport, buf, len);

	LOG_DBG("collect = %d", ret);

	/*
	 * Collection can fail only due to failing to allocate memory or by receiving
	 * more data than expected.
	 */
	if (ret == -ENOMEM) {
		/* Failed to collect the buffer */
		return -ENOMEM;
	} else if (ret < 0) {
		smp_reassembly_drop(&smp_rpc_transport);
		return ret;
	}

	/* No more bytes are expected for this packet */
	if (ret == 0) {
		smp_reassembly_complete(&smp_rpc_transport, false);
	}

	return 0;
#else
	struct net_buf *nb;	

	nb = smp_packet_alloc();
	if (!nb)
	{
		LOG_ERR("net buf alloc failed");
		return -ENOMEM;
	}
	net_buf_add_mem(nb, buf, len);
	smp_rx_req(&smp_rpc_transport, nb);	

	return 0;
#endif	
}

static void rpc_app_bt_smp_receive_cb(const struct nrf_rpc_group *group,
				       struct nrf_rpc_cbor_ctx *ctx, void *handler_data)
{	
	struct zcbor_string zst = {0};
	int err;	
	uint8_t buf[512];

	if (!zcbor_bstr_decode(ctx->zs, &zst) || zst.len > sizeof(buf)) {
		err = -NRF_EBADMSG;
		LOG_ERR("cbor decode err len %x", zst.len);		
	}
	else
	{	
		LOG_DBG("decoded done len %x", zst.len);
		memcpy(buf, zst.value, zst.len);	
		err = smp_receive_data(buf, zst.len);
	}

	nrf_rpc_cbor_decoding_done(group, ctx);

	rsp_error_code_send(group, err);
}

NRF_RPC_CBOR_CMD_DECODER(rpc_smp, rpc_app_bt_smp_receive,
			 RPC_COMMAND_NET_BT_SMP_RECEIVE_CB,
			 rpc_app_bt_smp_receive_cb, NULL);


static void rsp_error_code_handle(const struct nrf_rpc_group *group, struct nrf_rpc_cbor_ctx *ctx,
			   void *handler_data)
{
	int32_t val;

	if (zcbor_int32_decode(ctx->zs, &val)) {
		*(int *)handler_data = (int)val;
	} else {
		*(int *)handler_data = -NRF_EINVAL;
	}
}

int rpc_app_bt_smp_send(uint8_t *buffer, uint16_t length)
{
	int err;
	int result;
	struct nrf_rpc_cbor_ctx ctx;

	if (!buffer || length < 1) {
		LOG_ERR("rpc app send err");
		return -NRF_EINVAL;
	}	

	NRF_RPC_CBOR_ALLOC(&rpc_smp, ctx, CBOR_BUF_SIZE + length);
	
	zcbor_bstr_encode_ptr(ctx.zs, buffer, length);	

	err = nrf_rpc_cbor_cmd(&rpc_smp, RPC_COMMAND_APP_BT_SMP_SEND, &ctx,
			       rsp_error_code_handle, &result);
	if (err) {
		return err;
	}

	return result;
}
/**
 * Transmits the specified SMP response.
 */
static int smp_rpc_tx_pkt(struct net_buf *nb)
{	
	int rc;
	LOG_HEXDUMP_DBG(nb->data, nb->len, "rpc app send");
	rc = rpc_app_bt_smp_send(nb->data, nb->len);
	smp_packet_free(nb);
	return rc;
}

int rpc_app_bt_smp_get_mtu(void)
{
	int err;
	int result;
	struct nrf_rpc_cbor_ctx ctx;

	NRF_RPC_CBOR_ALLOC(&rpc_smp, ctx, CBOR_BUF_SIZE);

	err = nrf_rpc_cbor_cmd(&rpc_smp, RPC_COMMAND_APP_BT_SMP_GET_MTU, &ctx,
			       rsp_error_code_handle, &result);
	if (err < 0) {
		return err;
	}

	return result;
}

static uint16_t smp_rpc_get_mtu(const struct net_buf *nb)
{
	int mtu = rpc_app_bt_smp_get_mtu();
	return mtu < 0 ? 0: mtu;     
}

int smp_rpc_init(const struct device *dev)
{	
	ARG_UNUSED(dev);
	
	smp_transport_init(&smp_rpc_transport, smp_rpc_tx_pkt,
				  smp_rpc_get_mtu, NULL,
				  NULL, NULL);
	return 0;
}

SYS_INIT(smp_rpc_init, APPLICATION, CONFIG_APPLICATION_INIT_PRIORITY);
```

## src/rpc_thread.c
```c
/*
 * Copyright (c) 2020 Nordic Semiconductor ASA
 *
 * SPDX-License-Identifier: LicenseRef-BSD-5-Clause-Nordic
 */

#include <zephyr/kernel.h>
#include <zephyr/device.h>
#include <zephyr/devicetree.h>
#include <zephyr/drivers/gpio.h>
#include <stdio.h>
#include "rpc_app_api.h"
#include <zephyr/logging/log.h>
#include <zephyr/drivers/uart.h>

#define LOG_MODULE_NAME rpc_thread
LOG_MODULE_REGISTER(LOG_MODULE_NAME);

extern struct k_sem sem_rpc_tx;

static void app2net_send_example(void)
{
	static uint8_t cnt;
	int err;
	uint8_t buffer[20];


	snprintf(buffer, 10, "RPC_app_%d", cnt++);		
	buffer[9] = 0;		
	err = app2net_send_nus(buffer, 10);
	if (err) {
		LOG_ERR("app2net nus send err %d", err);			
	}
	else
	{
		LOG_HEXDUMP_INF(buffer, 10, "app2net nus:");
	}	
}

void rpc_thread(void)
{
	LOG_INF("**dual core communication example by RPC encapsulated API");

	k_sem_take(&sem_rpc_tx, K_FOREVER);	

	while (1) {	
		LOG_INF("RPC thread @ appcore");		
		app2net_send_example();
		k_sleep(K_SECONDS(2));
	}
}

K_THREAD_DEFINE(rpc_thread_id, 1024, rpc_thread, NULL, NULL,
		NULL, 6, 0, 0);
```

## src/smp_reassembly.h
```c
/*
 * Copyright (c) 2022 Nordic Semiconductor ASA
 *
 * SPDX-License-Identifier: Apache-2.0
 */

#ifndef ZEPHYR_INCLUDE_MGMT_SMP_REASSEMBLY_H_
#define ZEPHYR_INCLUDE_MGMT_SMP_REASSEMBLY_H_

#ifdef __cplusplus
extern "C" {
#endif

struct smp_transport;

/**
 * @brief Allocates a net_buf for holding an mcumgr request or response.
 *
 * @return      A newly-allocated buffer net_buf on success;
 *              NULL on failure.
 */
struct net_buf *smp_packet_alloc(void);

/**
 * @brief Frees an mcumgr net_buf
 *
 * @param nb    The net_buf to free.
 */
void smp_packet_free(struct net_buf *nb);

/**
 * Initialize re-assembly context within smp_transport
 *
 * @param smpt	the SMP transport.
 *
 * Note: for efficiency there is no NULL check on @p smpt pointer and it is caller's responsibility
 * to validate the pointer before passing it to this function.
 */
void smp_reassembly_init(struct smp_transport *smpt);

/**
 * Collect data to re-assembly buffer
 *
 * The function adds data to the end of current re-assembly buffer; it will allocate new buffer
 * if there isn't one allocated.
 *
 * Note: Currently the function is not able to concatenate buffers so re-assembled packet needs
 * to fit into one buffer.
 *
 * @param smpt	the SMP transport;
 * @param buf	buffer with data to add;
 * @param len	length of data to add;
 *
 * Note: For efficiency there are ot NULL checks on @p smpt and @p buf pointers and it is caller's
 * responsibility to make sure these are not NULL.  Also @p len should not be 0 as there is no
 * point in passing an empty fragment for re-assembly.
 *
 * @return	number of expected bytes left to complete the packet, 0 means buffer is complete
 *		and no more fragments are expected;
 *		-ENOSR if a packet length, read from header, is bigger than CONFIG_MCUMGR_BUF_SIZE,
 *		which means there is no way to fit it in the configured buffer;
 *		-EOVERFLOW if attempting to add a fragment that would make complete packet larger
 *		than expected;
 *		-ENOMEM if failed to allocate a new buffer for packet assembly;
 *		-ENODATA if the first received fragment was not big enough to figure out a size
 *		of the packet; MTU is set too low;
 */
int smp_reassembly_collect(struct smp_transport *smpt, const void *buf, uint16_t len);

/**
 * Return number of expected bytes to complete the packet
 *
 * @param smpt	the SMP transport;
 *
 * Note: for efficiency there is no NULL check on @p smpt pointer and it is caller's responsibility
 * to validate the pointer before passing it to this function.
 *
 * @return	number of bytes needed to complete the packet;
 *		-EINVAL if there is no packet in re-assembly;
 */
int smp_reassembly_expected(const struct smp_transport *smpt);

/**
 * Pass packet for further processing
 *
 * Checks if the packet has enough data to be re-assembled and passes it for further processing.
 * If successful then the re-assembly context in @p smpt will indicate that there is no
 * re-assembly in progress.
 * The function can be forced to pass a data for processing even if the packet is not complete,
 * in which case it is users responsibility to use the user data, passed with the packet, to notify
 * receiving end of such case.
 *
 * @param smpt	the SMP transport;
 * @param force	process anyway;
 *
 * Note: for efficiency there is no NULL check on @p smpt pointer and it is caller's responsibility
 * to validate the pointer before passing it to this function.
 *
 * @return	0 on success and not forced;
 *		expected number of bytes if forced to complete buffer with not enough data;
 *		-EINVAL if there is no re-assembly in progress;
 *		-ENODATA if there is not enough data to consider packet re-assembled, it has not
 *		been passed further.
 */
int smp_reassembly_complete(struct smp_transport *smpt, bool force);

/**
 * Drop packet and release buffer
 *
 * @param smpt	the SMP transport;
 *
 * Note: for efficiency there is no NULL check on @p smpt pointer and it is caller's responsibility
 * to validate the pointer before passing it to this function.
 *
 * @return	0 on success;
 *		-EINVAL if there is no re-assembly in progress.
 */
int smp_reassembly_drop(struct smp_transport *smpt);

/**
 * Get "user data" pointer for current packet re-assembly
 *
 * @param smpt	the SMP transport;
 *
 * Note: for efficiency there is no NULL check on @p smpt pointer and it is caller's responsibility
 * to validate the pointer before passing it to this function.
 *
 * @return	pointer to "user data" of CONFIG_MCUMGR_BUF_USER_DATA_SIZE size;
 *		NULL if no re-assembly in progress.
 */
void *smp_reassembly_get_ud(const struct smp_transport *smpt);

#ifdef __cplusplus
}
#endif

#endif /* ZEPHYR_INCLUDE_MGMT_SMP_REASSEMBLY_H_ */
```

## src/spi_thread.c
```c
/*
 * Copyright (c) 2020 Nordic Semiconductor ASA
 *
 * SPDX-License-Identifier: LicenseRef-BSD-5-Clause-Nordic
 */

#include <zephyr/kernel.h>
#include <zephyr/device.h>
#include <zephyr/devicetree.h>
#include <zephyr/drivers/gpio.h>
#include <zephyr/logging/log.h>
#include <zephyr/drivers/spi.h>

#define LOG_MODULE_NAME spi_thread
LOG_MODULE_REGISTER(LOG_MODULE_NAME);

#define DELAY_SPI_CS_ACTIVE_US 2
#define TEST_STRING "Nordic"

const struct device *spi_dev;
extern struct k_sem sem_spi_txrx;

static int spi_data_exchange(void)
{
    int err;
    struct spi_cs_control cs_ctrl;
    struct spi_config spi_cfg = {0};

	spi_cfg.frequency = 8000000U;
	spi_cfg.operation = SPI_WORD_SET(8);

	cs_ctrl.gpio.port = DEVICE_DT_GET(DT_GPIO_CTLR(DT_NODELABEL(my_spi), cs_gpios));
	if (!cs_ctrl.gpio.port) {
        LOG_ERR("cannot find CS GPIO device");
		return -ENODEV;
	}

	cs_ctrl.gpio.pin = DT_GPIO_PIN(DT_NODELABEL(my_spi), cs_gpios);
	cs_ctrl.gpio.dt_flags = DT_GPIO_FLAGS(DT_NODELABEL(my_spi), cs_gpios);

	cs_ctrl.delay = DELAY_SPI_CS_ACTIVE_US;

	spi_cfg.cs = &cs_ctrl;

	uint8_t buf[] = TEST_STRING;
    uint8_t data[] = TEST_STRING;

	struct spi_buf spi_buf[2] = {
		{
			.buf = buf,
			.len = sizeof(buf),
		},
		{
			.buf = data,
			.len = sizeof(data)
		}
	};
    
	const struct spi_buf_set tx_set = {
		.buffers = spi_buf,
		.count = 1
	};

	const struct spi_buf_set rx_set = {
		.buffers = spi_buf,
		.count = 1
	};

	// const struct spi_buf_set tx_set = {
	// 	.buffers = spi_buf,
	// 	.count = 2
	// };

	// const struct spi_buf_set rx_set = {
	// 	.buffers = spi_buf,
	// 	.count = 2
	// };    

	err = spi_transceive(spi_dev, &spi_cfg, &tx_set, &rx_set);
    
    if (err)
    {
        LOG_ERR("SPI transcation failed err %d", err);
    }
    else
    {
        LOG_HEXDUMP_INF(rx_set.buffers->buf, rx_set.buffers->len, "Received SPI data: ");
    }

    return err;

}

void spi_thread(void)
{	
	
	LOG_INF("** SPI master example **");
	LOG_INF("This example is ported from nRF5_SDK\\examples\\peripheral\\spi");
	LOG_INF("The related spis example is from nRF5_SDK\\examples\\peripheral\\spis");
	
	spi_dev = device_get_binding(DT_NODE_FULL_NAME(DT_NODELABEL(my_spi)));
	if (!spi_dev) {
		LOG_ERR("SPIM driver not found.\n");
		return;
	}
    k_sem_take(&sem_spi_txrx, K_FOREVER);
	while (1) {                
        LOG_INF("spi master thread");
        spi_data_exchange();
        k_sleep(K_MSEC(800)); 
	}
}

K_THREAD_DEFINE(spi_thread_id, 1024, spi_thread, NULL, NULL,
		NULL, 7, 0, 0);
```

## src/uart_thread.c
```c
/*
 * Copyright (c) 2020 Nordic Semiconductor ASA
 *
 * SPDX-License-Identifier: LicenseRef-BSD-5-Clause-Nordic
 */

#include <zephyr/kernel.h>
#include <zephyr/device.h>
#include <zephyr/devicetree.h>
#include <zephyr/drivers/gpio.h>
#include <stdio.h>
#include <zephyr/logging/log.h>
#include <zephyr/drivers/uart.h>
#include <zephyr/drivers/gpio.h>
#include "nrf_rpc_tr.h"
#include "rpc_app_api.h"

#define LOG_MODULE_NAME uart_thread
LOG_MODULE_REGISTER(LOG_MODULE_NAME);

#define MY_UARTE			DT_NODELABEL(uart1)
#define UART_DEVICE_NAME         DT_NODE_FULL_NAME(MY_UARTE)

#define UART_BUF_SIZE 255
#define UART_WAIT_FOR_BUF_DELAY K_MSEC(100)
#define UART_WAIT_FOR_RX 10000

static const struct device *uart;

struct uart_data_t {
	void *fifo_reserved;
	uint8_t data[UART_BUF_SIZE];
	uint16_t len;
};

static uint8_t uart_rx_buf[2][UART_BUF_SIZE];
static uint8_t *next_buf = uart_rx_buf[1];

static K_FIFO_DEFINE(fifo_uart_tx_data);
static K_FIFO_DEFINE(fifo_uart_rx_data);


static void uart_cb(const struct device *dev, struct uart_event *evt, void *user_data)
{
	ARG_UNUSED(dev);
	int err;

	switch (evt->type) {
	case UART_TX_DONE:
	{
		struct uart_data_t *buf;
		struct uart_data_t *buf2;
		
		buf = CONTAINER_OF(evt->data.tx.buf, struct uart_data_t,  data);		
		LOG_INF("UART_TX_DONE %d", evt->data.tx.len);
		k_free(buf);

		buf2 = k_fifo_get(&fifo_uart_tx_data, K_NO_WAIT);
		if (!buf2) {
			return;
		}

		if (uart_tx(uart, buf2->data, buf2->len, SYS_FOREVER_MS)) {
			LOG_WRN("uart_tx fail @ cb");
		}
	}
		break;

	case UART_RX_RDY:
	{
		struct uart_data_t *buf = k_malloc(sizeof(struct uart_data_t));
		memcpy(buf->data, &evt->data.rx.buf[evt->data.rx.offset], evt->data.rx.len);	
		buf->len = evt->data.rx.len;		
		k_fifo_put(&fifo_uart_rx_data, buf);
		LOG_INF("UART_RX_RDY %d", buf->len);
	}
		break;

	case UART_RX_DISABLED:
		LOG_INF("UART_RX_DISABLED");
		err = uart_rx_enable(uart, uart_rx_buf[0], sizeof(uart_rx_buf[0]), UART_WAIT_FOR_RX);
		if (err) {
			LOG_ERR("UART RX enable failed: %d", err);			
		}
		break;

	case UART_RX_BUF_REQUEST:
		err = uart_rx_buf_rsp(uart, next_buf,
			sizeof(uart_rx_buf[0]));
		if (err) {
			LOG_WRN("UART RX buf rsp: %d", err);
		}		
		break;

	case UART_RX_BUF_RELEASED:
		LOG_INF("UART_RX_BUF_RELEASED");
		next_buf = evt->data.rx_buf.buf;
		break;

	case UART_TX_ABORTED:
		LOG_INF("UART_TX_ABORTED");
		break;

	default:
		break;
	}
}

static int uart_init(void)
{
	int err;
	
	uart = device_get_binding(UART_DEVICE_NAME);
	if (!uart) {
		return -ENXIO;
	}

	err = uart_callback_set(uart, uart_cb, NULL);
	if (err) {
		return err;
	}

	return uart_rx_enable(uart, uart_rx_buf[0], sizeof(uart_rx_buf[0]), UART_WAIT_FOR_RX);

}

int my_uart_send(const uint8_t *buf, size_t len)
{
	int err;
	struct uart_data_t *tx = k_malloc(sizeof(*tx));

	if (!tx) {
		LOG_WRN("Not able to allocate UART send data buffer");
		return -ENOMEM; 
	}

	memcpy(tx->data, buf, len);	
	tx->len = len;
	err = uart_tx(uart, tx->data, tx->len, SYS_FOREVER_MS);
	if (err) {
		LOG_WRN("buffer uart tx data for later retry");
		k_fifo_put(&fifo_uart_tx_data, tx);
	}
	return err;		
}

void uart_thread(void)
{    
	LOG_INF("**high speed UART example");

	uart_init();

	while (1) {

		/* Send the UART data back to the peer. Wait indefinitely*/
		struct uart_data_t *buf = k_fifo_get(&fifo_uart_rx_data,
						     K_FOREVER);
#ifdef CONFIG_RPC_REMOTE_API
		if (is_ble_connected())
		{
			int err = app2net_send_nus(buf->data,buf->len);
			if (err) {
				LOG_WRN("app2net_send_nus err %d", err);			
			}	
		}
#endif

		my_uart_send(buf->data,buf->len);
		
		LOG_HEXDUMP_INF(buf->data, buf->len, "uart received:");
		k_free(buf);					
	}
}

K_THREAD_DEFINE(uart_thread_id, 1024, uart_thread, NULL, NULL,
		NULL, 5, 0, 0);
```
